# V32F20x_CM33 register map
File version: 1.0.3
CPU: CM33 r0p4, little endian, MPU, FPU, DSP, 3 interrupt priority bits, 8 SAU regions
Registers are 32-bit, read-write, reset 0x0 unless marked. A register's access mark holds for its fields unless they carry their own. Offsets are from the block's base; [hi:lo] are bit positions; {n}, {i} and the like mark numbered series.

## DAC — DAC Peripheral Interface
Base 0x400A0000
Same registers: SEC_DAC 0x500A0000
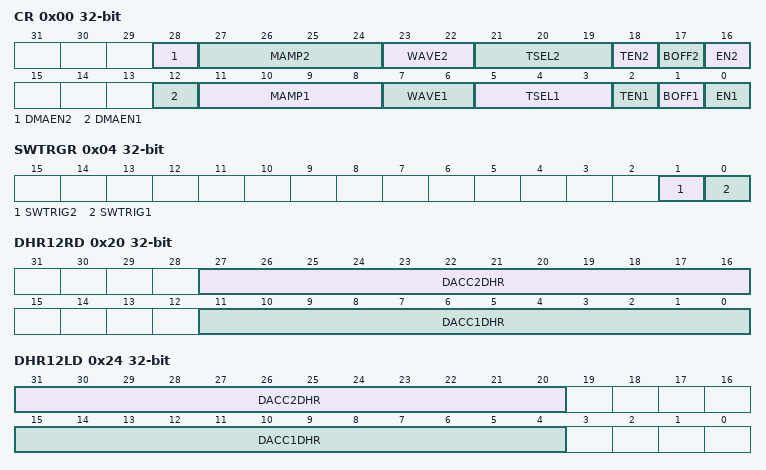
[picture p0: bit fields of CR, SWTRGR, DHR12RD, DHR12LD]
0x00 CR — DAC_CR
  [28] DMAEN2 — DAC channel 2 DMA enable
  [27:24] MAMP2 — DAC channel 2 mask/ amplitude selector
  [23:22] WAVE2 — DAC channel 2 noise triangle wave generation enable
  [21:19] TSEL2 — DAC channel 2 trigger selection
  [18] TEN2 — DAC channel 2 trigger enable
  [17] BOFF2 — DAC channel2 output buffer disable
  [16] EN2 — DAC channel 2 enable
  [12] DMAEN1 — DAC channel 1 DMA enable
  [11:8] MAMP1 — DAC channel 1 mask/ amplitude selector
  [7:6] WAVE1 — DAC channel 1 noise triangle wave generation enable
  [5:3] TSEL1 — DAC channel 1 trigger selection
  [2] TEN1 — DAC channel 1 trigger enable
  [1] BOFF1 — DAC channel 1 output buffer disable
  [0] EN1 — DAC channel 1 enable
0x04 SWTRGR — DAC_SWTRGR
  [1] SWTRIG2 — DAC channel 2 software trigger
  [0] SWTRIG1 — DAC channel1 software trigger
0x08 DHR12R1 — DAC_DHR12R1
  [11:0] DACC1DHR — DAC channel1 12-bit right-aligned data
0x0C DHR12L1 — DAC_DHR12L1
  [15:4] DACC1DHR — DAC channel1 12-bit left-aligned data
0x10 DHR8R1 — DAC_DHR8R1
  [7:0] DACC1DHR — DAC channel1 8-bit right-aligned data
0x14 DHR12R2 — DAC_DHR12R2
  [11:0] DACC2DHR — DAC channel2 12-bit right-aligned data
0x18 DHR12L2 — DAC_DHR12L2
  [15:4] DACC2DHR — DAC channel2 12-bit left-aligned data
0x1C DHR8R2 — DAC_DHR8R2
  [7:0] DACC2DHR — DAC channel2 8-bit right-aligned data
0x20 DHR12RD — DAC_DHR12RD
  [27:16] DACC2DHR — DAC channel2 12-bit right-aligned data
  [11:0] DACC1DHR — DAC channel1 12-bit right-aligned data
0x24 DHR12LD — DAC_DHR12LD
  [31:20] DACC2DHR — DAC channel2 12-bit left-aligned data
  [15:4] DACC1DHR — DAC channel1 12-bit left-aligned data
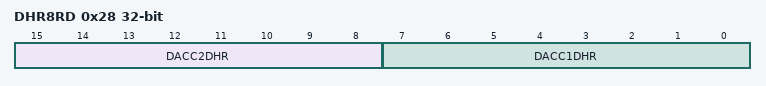
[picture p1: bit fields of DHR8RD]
0x28 DHR8RD — DAC_DHR8RD
  [15:8] DACC2DHR — DAC channel2 8-bit right-aligned data
  [7:0] DACC1DHR — DAC channel1 8-bit right-aligned data
0x2C DOR1 ro — DAC_DOR1
  [11:0] DACC1DOR — DAC channel 1 data output
0x30 DOR2 ro — DAC_DOR2
  [11:0] DACC2DOR — DAC channel 2 data output

## EADC — EADC Peripheral Interface
Base 0x400A0800
Same registers: SEC_EADC 0x500A0800
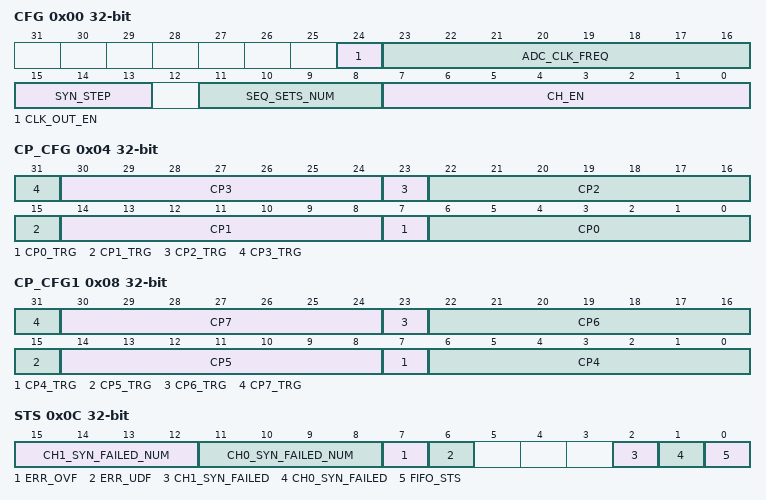
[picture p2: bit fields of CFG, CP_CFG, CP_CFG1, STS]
0x00 CFG
  [24] CLK_OUT_EN — ADC clock input or output enable:
  [23:16] ADC_CLK_FREQ — Output ADC clock frequency division number.
  [15:13] SYN_STEP — Width of 0 (1) in 01 sequence.
  [11:8] SEQ_SETS_NUM — Numbers of sets of sequence to abandon.
  [7:0] CH_EN — Channel Enable.
0x04 CP_CFG
  [8n+7] CP{n}_TRG (n=0..3) — Channel {n} capture point trigger edge:
  [30:24] CP3 — Capture point of channel 3
  [22:16] CP2 — Capture point of channel 2
  [14:8] CP1 — Capture point of channel 1
  [6:0] CP0 — Capture point of Channel 0
0x08 CP_CFG1
  [8n-25] CP{n}_TRG (n=4..7) — Channel {n} capture point trigger edge:
  [30:24] CP7 — Capture point of channel 7
  [22:16] CP6 — Capture point of channel 6
  [14:8] CP5 — Capture point of channel 5
  [6:0] CP4 — Capture point of Channel 4
0x0C STS
  [15:12] CH1_SYN_FAILED_NUM — Channel 1 synchronization failed times
  [11:8] CH0_SYN_FAILED_NUM — Channel 0 synchronization failed times
  [7] ERR_OVF — Error of overflow occur
  [6] ERR_UDF — Under flow error occur
  [2] CH1_SYN_FAILED — When CH1_SYN_FAILED_NUM is bigger than 5 this field will be set
  [1] CH0_SYN_FAILED — When CH0_SYN_FAILED_NUM is bigger than 5 this field will be set
  [0] FIFO_STS — FIFO STATUS
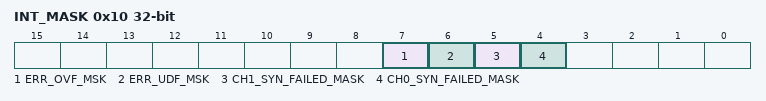
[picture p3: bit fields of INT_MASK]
0x10 INT_MASK
  [7] ERR_OVF_MSK — The interrupt mask of ERR_OVF_MSK
  [6] ERR_UDF_MSK — The interrupt mask of ERR_UDF
  [5] CH1_SYN_FAILED_MASK — The interrupt mask of CH1_SYN_FAILED
  [4] CH0_SYN_FAILED_MASK — The interrupt mask of CH0_SYN_FAILED:
0x20 CH_DATA
  [31:0] CH_DATA — Converted parallel data of Channel 0

## DCMI — DCMI Peripheral Interface
Base 0x40201000
Same registers: SEC_DCMI 0x50201000
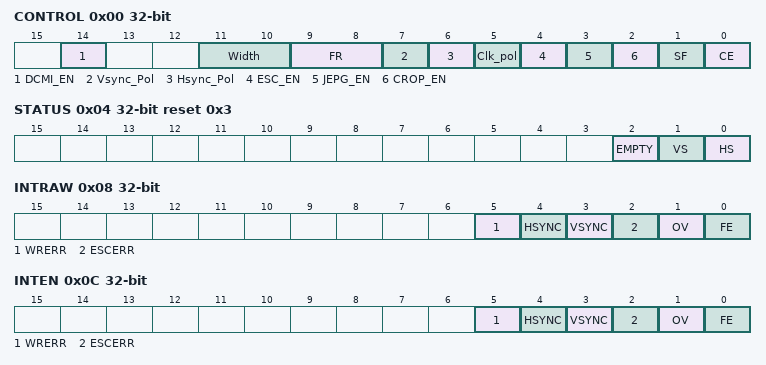
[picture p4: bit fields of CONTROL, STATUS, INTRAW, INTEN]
0x00 CONTROL — DCMI control register
  [14] DCMI_EN — 0: Disable DCMI
  [11:10] Width — Input data width
  [9:8] FR — Frame capture rate control
  [7] Vsync_Pol — Vsync(vertical synchronization) polarity
  [6] Hsync_Pol — Hsync(horizontal synchronization) polarity
  [5] Clk_pol — pixel clock polarity
  [4] ESC_EN — Embed synchronization select
  [3] JEPG_EN — Enable JPEG mode
  [2] CROP_EN — Enable Crop feature
  [1] SF — Enable signal frame capture feature
  [0] CE — Capture enable
0x04 STATUS ro reset 0x3 — DCMI status register
  [2] EMPTY — FIFO status
  [1] VS — Vertical synchronization status
  [0] HS — Horizontal synchronization status
0x08 INTRAW ro — DCMI raw interrupt register
  [5] WRERR — This bit is set when output data transfer get error
  [4] HSYNC — This bit is set when HSYNC signal be active
  [3] VSYNC — This bit is set when VSYNC signal be active
  [2] ESCERR — This bit is set when wrong embedded synchronizaiton
  [1] OV — This bit is set when FIFO overflow
  [0] FE — This bit is set when one frame captured is finished
0x0C INTEN ro — DCMI interrupt enable register
  [5] WRERR — Data transfer error interrupt enable
  [4] HSYNC — Hsync interrupt enable
  [3] VSYNC — Vsync interrupt enable
  [2] ESCERR — ESC error interrupt enable
  [1] OV — FIFO overflow interrupt enable
  [0] FE — Frame end interrupt enable
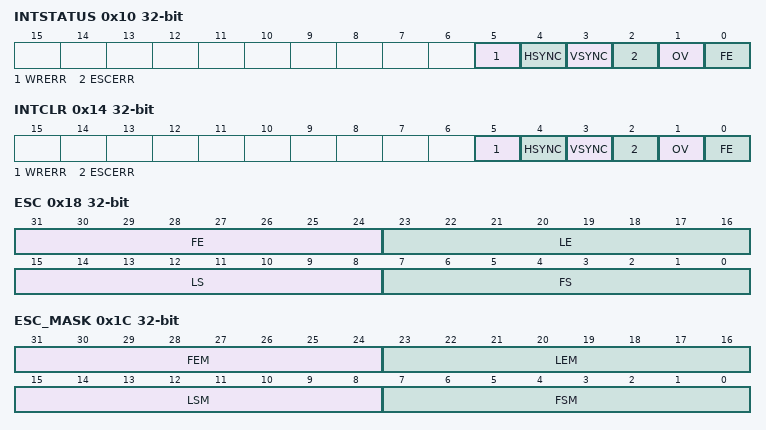
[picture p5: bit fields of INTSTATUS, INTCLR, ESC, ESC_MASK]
0x10 INTSTATUS ro — DCMI interrupt status register
  [5] WRERR — Output data transfer error interrupt status.
  [4] HSYNC — HSYNC interrupt status
  [3] VSYNC — VSYNC interrupt status
  [2] ESCERR — embedded synchronization code error interrupt status
  [1] OV — FIFO overflow interrupt status
  [0] FE — one frame captured finish interrupt status
0x14 INTCLR — DCMI interrupt clear register
  [5] WRERR — clear output data transfer error interrupt by write 1
  [4] HSYNC — clear HSYNC interrupt by write 1
  [3] VSYNC — clear VSYNC interrupt by write 1
  [2] ESCERR — clear embedded synchronization code error interrupt
  [1] OV — clear FIFO overflow interrupt by write 1
  [0] FE — clear one frame captured finish interrupt by write 1
0x18 ESC — DCMI embedded code register
  [31:24] FE — Frame end delimiter
  [23:16] LE — Line end delimiter
  [15:8] LS — Line start delimiter
  [7:0] FS — Frame start delimiter
0x1C ESC_MASK — DCMI embedded code mask register
  [31:24] FEM — Frame end delimiter mask
  [23:16] LEM — Line end delimiter mask
  [15:8] LSM — Line start delimiter mask
  [7:0] FSM — Frame start delimiter mask
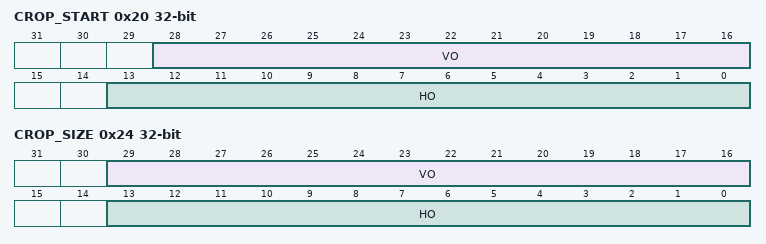
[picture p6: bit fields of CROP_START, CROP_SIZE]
0x20 CROP_START — DCMI crop window start register
  [28:16] VO — start Line number to be captured, previous line
  [13:0] HO — the number of pixel clocks to skip before stating a capture
0x24 CROP_SIZE — DCMI crop window size register
  [29:16] VO — Line numbers to be captured in each frame
  [13:0] HO — the number of pixel clocks to be captured each line
0x28 DATA ro — DCMI data register
  [31:0] DATA — Read received data from fifo.
